# f29h85x_adc_regs register map
Vendor: Texas Instruments
Peripheral module from a debugger description file (folder C29).
Registers are 32-bit, read-write, no defined reset value unless marked. A register's access mark holds for its fields unless they carry their own. Offsets are as the file gives them; lines under a group give offsets from that group; [hi:lo] are bit positions; {n}, {i} and the like mark numbered series; 'fields as' and 'values as' point back to an identical list; <NAME> marks a mode.

## ADC_REGS — ADC Registers
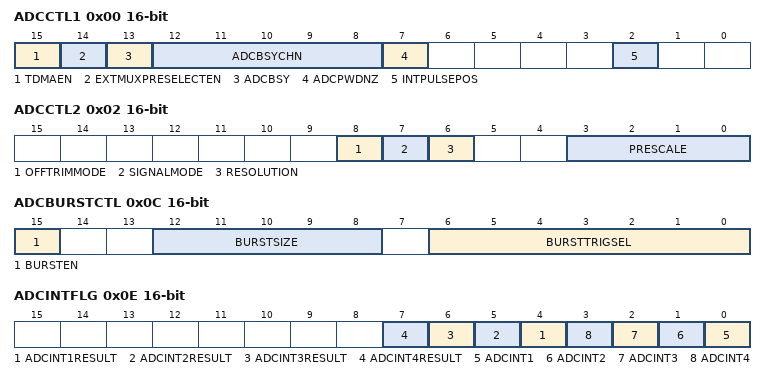
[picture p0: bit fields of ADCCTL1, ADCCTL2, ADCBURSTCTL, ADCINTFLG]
0x00 ADCCTL1 16-bit access per field — ADC Control 1 Register
  [15] TDMAEN rw — Enable Alternate DMA Timings
  [14] EXTMUXPRESELECTEN rw — External Mux Preselect Enable
  [13] ADCBSY ro — ADC Busy
  [12:8] ADCBSYCHN ro — ADC Busy Channel
  [7] ADCPWDNZ rw — ADC Power Down
  [2] INTPULSEPOS rw — ADC Interrupt Pulse Position
0x02 ADCCTL2 16-bit — ADC Control 2 Register
  [8] OFFTRIMMODE — Offset Trim Mode
  [7] SIGNALMODE — SOC Signaling Mode
  [6] RESOLUTION — SOC Conversion Resolution
  [3:0] PRESCALE — ADC Clock Prescaler
0x0C ADCBURSTCTL 16-bit — ADC Burst Control Register
  [15] BURSTEN — SOC Burst Mode Enable
  [12:8] BURSTSIZE — SOC Burst Size Select
  [6:0] BURSTTRIGSEL — SOC Burst Trigger Source Select
0x0E ADCINTFLG 16-bit ro — ADC Interrupt Flag Register
  [n+3] ADCINT{n}RESULT (n=1..4) — ADC Interrupt {n} Results Ready
  [n-1] ADCINT{n} (n=1..4) — ADC Interrupt {n} Flag
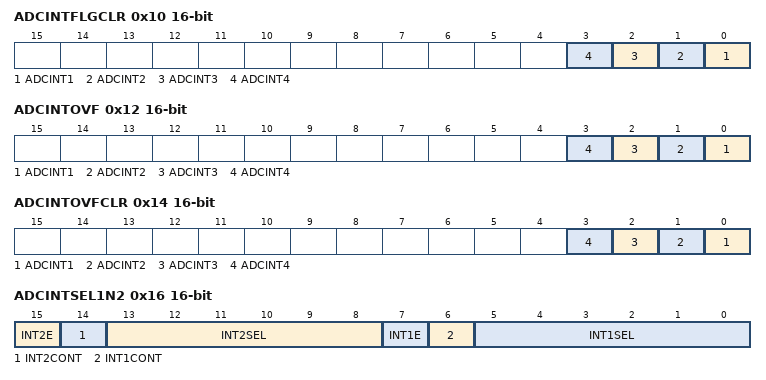
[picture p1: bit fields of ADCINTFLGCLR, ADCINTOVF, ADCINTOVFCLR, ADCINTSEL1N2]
0x10 ADCINTFLGCLR 16-bit — ADC Interrupt Flag Clear Register
  [n-1] ADCINT{n} (n=1..4) — ADC Interrupt {n} Flag Clear
0x12 ADCINTOVF 16-bit ro — ADC Interrupt Overflow Register
  [n-1] ADCINT{n} (n=1..4) — ADC Interrupt {n} Overflow Flags
0x14 ADCINTOVFCLR 16-bit — ADC Interrupt Overflow Clear Register
  [n-1] ADCINT{n} (n=1..4) — ADC Interrupt {n} Overflow Clear Bits
0x16 ADCINTSEL1N2 16-bit — ADC Interrupt 1 and 2 Selection Register
  [15] INT2E — ADCINT2 Interrupt Enable
  [14] INT2CONT — ADCINT2 Continue to Interrupt Mode
  [13:8] INT2SEL — ADCINT2 EOC Source Select
  [7] INT1E — ADCINT1 Interrupt Enable
  [6] INT1CONT — ADCINT1 Continue to Interrupt Mode
  [5:0] INT1SEL — ADCINT1 EOC Source Select
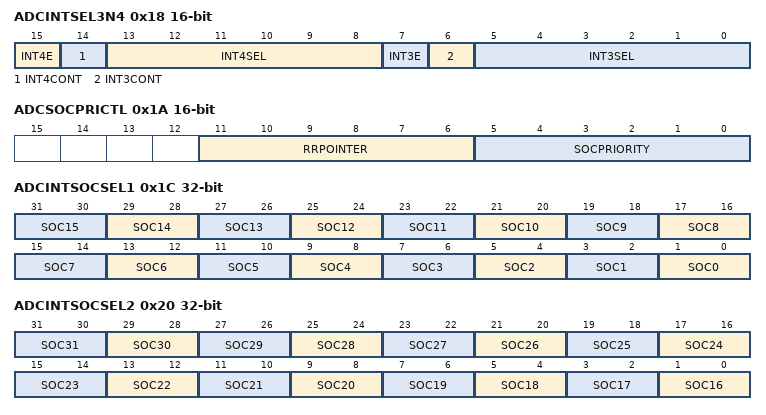
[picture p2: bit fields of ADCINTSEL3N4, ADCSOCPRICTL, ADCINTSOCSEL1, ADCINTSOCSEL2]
0x18 ADCINTSEL3N4 16-bit — ADC Interrupt 3 and 4 Selection Register
  [15] INT4E — ADCINT4 Interrupt Enable
  [14] INT4CONT — ADCINT4 Continue to Interrupt Mode
  [13:8] INT4SEL — ADCINT4 EOC Source Select
  [7] INT3E — ADCINT3 Interrupt Enable
  [6] INT3CONT — ADCINT3 Continue to Interrupt Mode
  [5:0] INT3SEL — ADCINT3 EOC Source Select
0x1A ADCSOCPRICTL 16-bit access per field — ADC SOC Priority Control Register
  [11:6] RRPOINTER ro — Round Robin Pointer
  [5:0] SOCPRIORITY rw
0x1C ADCINTSOCSEL1 — ADC Interrupt SOC Selection 1 Register
  [2n+1:2n] SOC{n} (n=0..15) — SOC{n} ADC Interrupt Trigger Select
0x20 ADCINTSOCSEL2 — ADC Interrupt SOC Selection 2 Register
  [2n-31:2n-32] SOC{n} (n=16..31) — SOC{n} ADC Interrupt Trigger Select
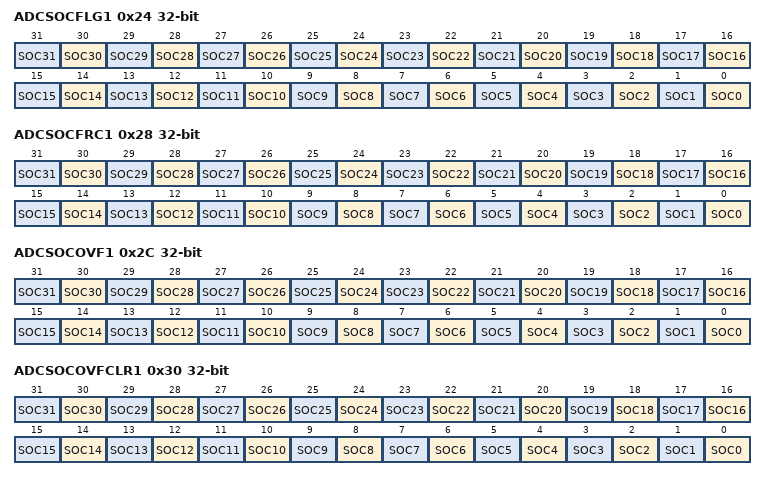
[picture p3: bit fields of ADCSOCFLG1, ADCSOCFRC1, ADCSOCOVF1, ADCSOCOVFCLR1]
0x24 ADCSOCFLG1 ro — ADC SOC Flag 1 Register
  [n] SOC{n} (n=0..31) — SOC{n} Start of Conversion Flag
0x28 ADCSOCFRC1 — ADC SOC Force 1 Register
  [n] SOC{n} (n=0..31) — SOC{n} Force Start of Conversion Bit
0x2C ADCSOCOVF1 ro — ADC SOC Overflow 1 Register
  [n] SOC{n} (n=0..31) — SOC{n} Start of Conversion Overflow Flag
0x30 ADCSOCOVFCLR1 — ADC SOC Overflow Clear 1 Register
  [n] SOC{n} (n=0..31) — SOC{n} Clear Start of Conversion Overflow Bit
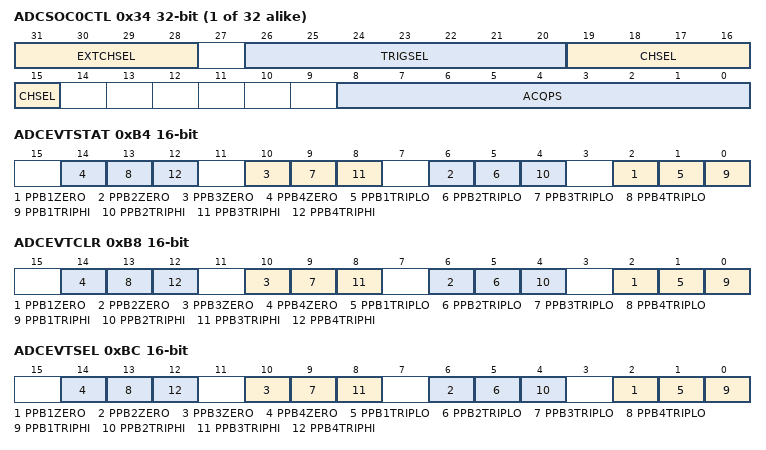
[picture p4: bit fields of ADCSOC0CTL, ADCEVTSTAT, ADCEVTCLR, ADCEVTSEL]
{0x34+4i} ADCSOC{i}CTL (i=0..31) — ADC SOC{i} Control Register
  [31:28] EXTCHSEL — SOC{i} External Channel Mux Select
  [26:20] TRIGSEL — SOC{i} Trigger Source Select
  [19:15] CHSEL — SOC{i} Channel Select
  [8:0] ACQPS — SOC{i} Acquisition Prescale
0xB4 ADCEVTSTAT 16-bit ro — ADC Event Status Register
  [4n-2] PPB{n}ZERO (n=1..4) — Post Processing Block {n} Zero Crossing Flag
  [4n-3] PPB{n}TRIPLO (n=1..4) — Post Processing Block {n} Trip Low Flag
  [4n-4] PPB{n}TRIPHI (n=1..4) — Post Processing Block {n} Trip High Flag
0xB8 ADCEVTCLR 16-bit — ADC Event Clear Register
  [4n-2] PPB{n}ZERO (n=1..4) — Post Processing Block {n} Zero Crossing Clear
  [4n-3] PPB{n}TRIPLO (n=1..4) — Post Processing Block {n} Trip Low Clear
  [4n-4] PPB{n}TRIPHI (n=1..4) — Post Processing Block {n} Trip High Clear
0xBC ADCEVTSEL 16-bit — ADC Event Selection Register
  [4n-2] PPB{n}ZERO (n=1..4) — Post Processing Block {n} Zero Crossing Event Enable
  [4n-3] PPB{n}TRIPLO (n=1..4) — Post Processing Block {n} Trip Low Event Enable
  [4n-4] PPB{n}TRIPHI (n=1..4) — Post Processing Block {n} Trip High Event Enable
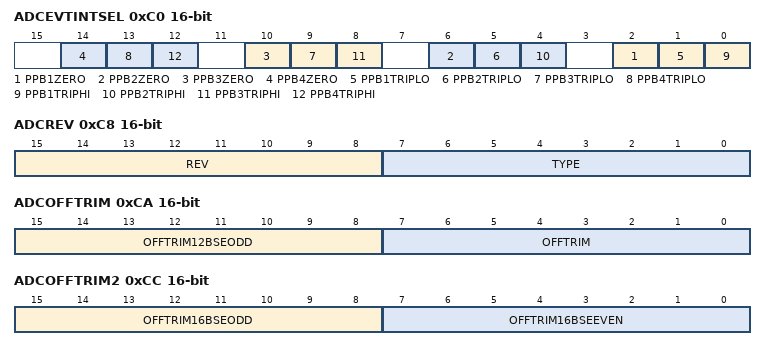
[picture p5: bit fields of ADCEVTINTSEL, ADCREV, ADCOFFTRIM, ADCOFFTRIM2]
0xC0 ADCEVTINTSEL 16-bit — ADC Event Interrupt Selection Register
  [4n-2] PPB{n}ZERO (n=1..4) — Post Processing Block {n} Zero Crossing Interrupt Enable
  [4n-3] PPB{n}TRIPLO (n=1..4) — Post Processing Block {n} Trip Low Interrupt Enable
  [4n-4] PPB{n}TRIPHI (n=1..4) — Post Processing Block {n} Trip High Interrupt Enable
0xC4 ADCOSDETECT 16-bit — ADC Open and Shorts Detect Register
  [2:0] DETECTCFG — ADC Opens and Shorts Detect Configuration
0xC6 ADCCOUNTER 16-bit ro
  [11:0] FREECOUNT — ADC Free Running Counter Value
0xC8 ADCREV 16-bit ro — ADC Revision Register
  [15:8] REV — ADC Revision
  [7:0] TYPE — ADC Type
0xCA ADCOFFTRIM 16-bit — ADC Offset Trim Register 1
  [15:8] OFFTRIM12BSEODD — ADC Offset Trim 12B SE Odd
  [7:0] OFFTRIM — ADC Offset Trim 12B SE Even
0xCC ADCOFFTRIM2 16-bit — ADC Offset Trim Register 2
  [15:8] OFFTRIM16BSEODD — ADC Offset Trim 16B SE Odd
  [7:0] OFFTRIM16BSEEVEN — ADC Offset Trim 16B SE Even
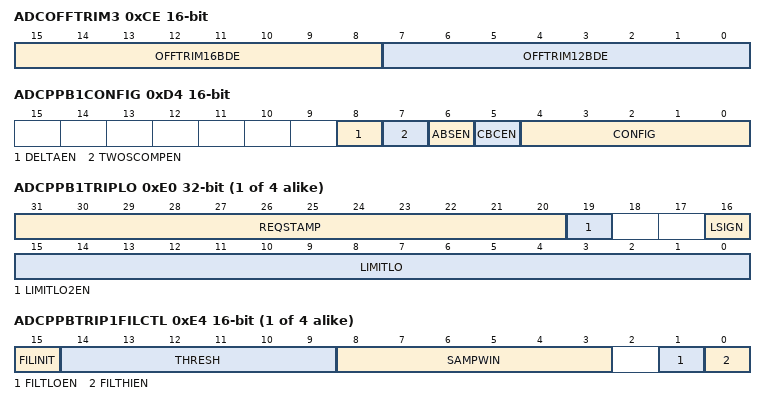
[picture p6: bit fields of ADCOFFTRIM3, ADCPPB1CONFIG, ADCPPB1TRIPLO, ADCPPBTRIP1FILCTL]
0xCE ADCOFFTRIM3 16-bit — ADC Offset Trim Register 3
  [15:8] OFFTRIM16BDE — ADC Offset Trim 16B DE
  [7:0] OFFTRIM12BDE — ADC Offset Trim 12B DE
0xD4 ADCPPB1CONFIG 16-bit — ADC PPB{#} Config Register
  [8] DELTAEN — ADC Post Processing Block 1 Last Sample Delta Enable
  [7] TWOSCOMPEN — ADC Post Processing Block 1 Two's Complement Enable
  [6] ABSEN — ADC Post Processing Block 1 Absolute Enable
  [5] CBCEN — Cycle By Cycle Enable
  [4:0] CONFIG — ADC Post Processing Block 1 Configuration
{0xB6+0x20*i} ADCPPB{i}STAMP 16-bit ro (i=1..4) — ADC PPB{i} Sample Delay Time Stamp Register
  [11:0] DLYSTAMP — ADC Post Processing Block {i} Delay Time Stamp
{0xB8+0x20*i} ADCPPB{i}OFFCAL 16-bit (i=1..4) — ADC PPB{i} Offset Calibration Register
  [9:0] OFFCAL — ADC Post Processing Block Offset Correction
{0xBA+0x20*i} ADCPPB{i}OFFREF 16-bit (i=1..4) — ADC PPB{i} Offset Reference Register
  [15:0] OFFREF — ADC Post Processing Block {i} Offset Reference
{0xBC+0x20*i} ADCPPB{i}TRIPHI (i=1..4) — ADC PPB{i} Trip High Register
  [23:0] LIMITHI — ADC Post Processing Block {i} Trip High Limit
{0xC0+0x20*i} ADCPPB{i}TRIPLO access per field (i=1..4) — ADC PPB{i} Trip Low/Trigger Time Stamp Register
  [31:20] REQSTAMP ro — ADC Post Processing Block {i} Request Time Stamp
  [19] LIMITLO2EN rw — Extended Low Limit 2 Enable
  [16] LSIGN rw — Low Limit Sign Bit
  [15:0] LIMITLO rw — ADC Post Processing Block {i} Trip Low Limit
{0xC4+0x20*i} ADCPPBTRIP{i}FILCTL 16-bit (i=1..4) — ADCEVT{i} Trip High Filter Control Register
  [15] FILINIT — Filter Initialization Bit
  [14:9] THRESH — Majority Voting Threshold
  [8:3] SAMPWIN — Sample Window
  [1] FILTLOEN — ADCPPB{i} TRIPLO Filter Enable
  [0] FILTHIEN — ADCPPB{i} TRIPHI Filter Enable
{0xC8+0x20*i} ADCPPBTRIP{i}FILCLKCTL (i=1..4) — ADCEVT{i} Trip High Filter Prescale Control Register
  [15:0] CLKPRESCALE — Filter Clock Prescale
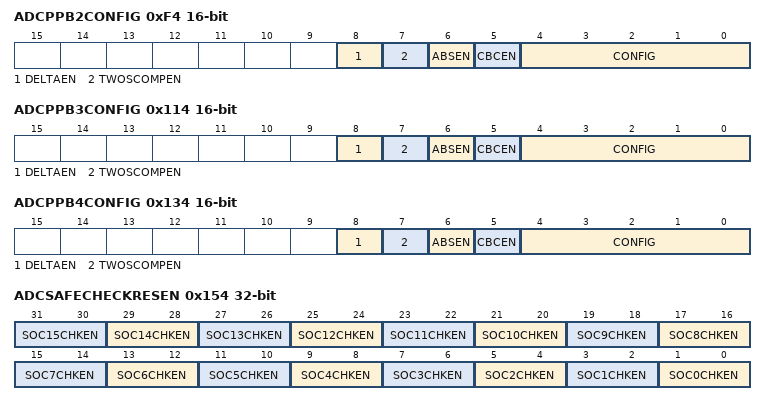
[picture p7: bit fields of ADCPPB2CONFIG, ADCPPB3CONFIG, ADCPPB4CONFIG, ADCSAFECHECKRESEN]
0xF4 ADCPPB2CONFIG 16-bit — ADC PPB{#} Config Register
  [8] DELTAEN — ADC Post Processing Block 2 Last Sample Delta Enable
  [7] TWOSCOMPEN — ADC Post Processing Block 2 Two's Complement Enable
  [6] ABSEN — ADC Post Processing Block 2 Absolute Enable
  [5] CBCEN — Cycle By Cycle Enable
  [4:0] CONFIG — ADC Post Processing Block 2 Configuration
0x114 ADCPPB3CONFIG 16-bit — ADC PPB{#} Config Register
  [8] DELTAEN — ADC Post Processing Block 3 Last Sample Delta Enable
  [7] TWOSCOMPEN — ADC Post Processing Block 3 Two's Complement Enable
  [6] ABSEN — ADC Post Processing Block 3 Absolute Enable
  [5] CBCEN — Cycle By Cycle Enable
  [4:0] CONFIG — ADC Post Processing Block 3 Configuration
0x134 ADCPPB4CONFIG 16-bit — ADC PPB{#} Config Register
  [8] DELTAEN — ADC Post Processing Block 4 Last Sample Delta Enable
  [7] TWOSCOMPEN — ADC Post Processing Block 4 Two's Complement Enable
  [6] ABSEN — ADC Post Processing Block 4 Absolute Enable
  [5] CBCEN — Cycle By Cycle Enable
  [4:0] CONFIG — ADC Post Processing Block 4 Configuration
0x154 ADCSAFECHECKRESEN — ADC Safe Check Result Enable Register
  [2n+1:2n] SOC{n}CHKEN (n=0..15) — ADC SOC{n} Safety Checker Result Enable
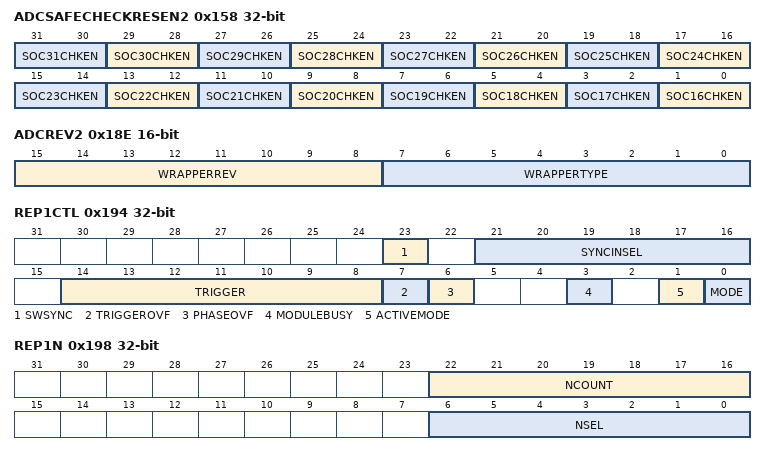
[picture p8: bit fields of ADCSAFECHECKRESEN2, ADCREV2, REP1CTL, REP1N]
0x158 ADCSAFECHECKRESEN2 — ADC Safe Check Result Enable 2 Register
  [2n-31:2n-32] SOC{n}CHKEN (n=16..31) — ADC SOC{n} Safety Checker Result Enable
0x172 ADCINTCYCLE 16-bit — ADC Early Interrupt Generation Cycle
  [15:0] DELAY — Delay from ADCSOC fall edge to early interrupt generation.
{0x170+4i} ADCINLTRIM{i} (i=1..6) — ADC Linearity Trim {i} Register
  [31:0] INLTRIM{32i-1}TO{32i-32} — ADC Linearity Trim Bits {32i-1}-{32i-32}
0x18E ADCREV2 16-bit ro — ADC Wrapper Revision Register
  [15:8] WRAPPERREV — ADC Wrapper Revision
  [7:0] WRAPPERTYPE — ADC Wrapper Type
0x194 REP1CTL access per field — ADC Trigger Repeater 1 Control Register
  [23] SWSYNC rw — ADC Trigger Repeater 1 Software Sync.
  [21:16] SYNCINSEL rw — ADC Trigger Repeater 1 Sync. In Select
  [14:8] TRIGGER rw — ADC Trigger Repeater 1 Trigger Select
  [7] TRIGGEROVF rw — ADC Trigger Repeater 1 Oversampled Trigger Overflow
  [6] PHASEOVF rw — ADC Trigger Repeater 1 Phase Delay Overflow
  [3] MODULEBUSY ro — ADC Trigger Repeater 1 Module Busy
  [1] ACTIVEMODE ro — ADC Trigger Repeater 1 Active Mode
  [0] MODE rw — ADC Trigger Repeater 1 Mode Select
0x198 REP1N access per field — ADC Trigger Repeater 1 N Select Register
  [22:16] NCOUNT ro — ADC Trigger Repeater 1 Trigger Counter
  [6:0] NSEL rw — ADC Trigger Repeater 1 Trigger Number Selection
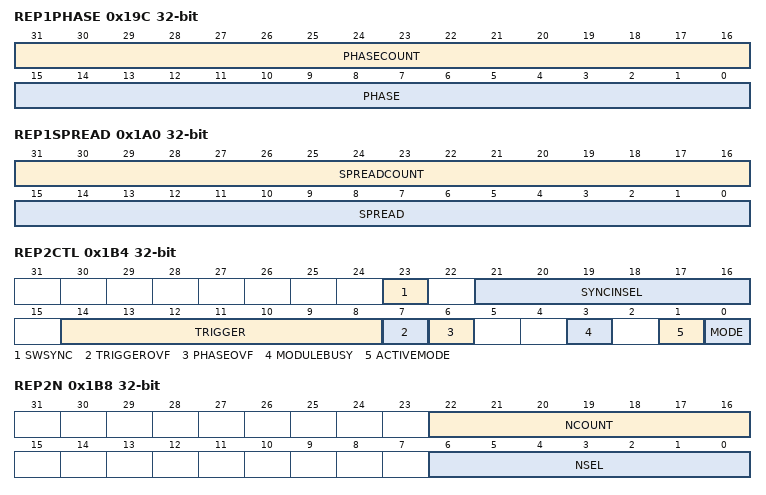
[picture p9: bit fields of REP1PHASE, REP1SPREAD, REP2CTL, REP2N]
0x19C REP1PHASE access per field — ADC Trigger Repeater 1 Phase Select Register
  [31:16] PHASECOUNT ro — ADC Trigger Repeater 1 Phase Delay Status
  [15:0] PHASE rw — ADC Trigger Repeater 1 Phase Delay Configuration
0x1A0 REP1SPREAD access per field — ADC Trigger Repeater 1 Spread Select Register
  [31:16] SPREADCOUNT ro — ADC Trigger Repeater 1 Spread Delay Status
  [15:0] SPREAD rw — ADC Trigger Repeater 1 Spread Delay Configuration
0x1A4 REP1FRC 16-bit — ADC Trigger Repeater 1 Software Force Register
  [0] SWFRC — ADC Trigger Repeater 1 Software Force
0x1B4 REP2CTL access per field — ADC Trigger Repeater 2 Control Register
  [23] SWSYNC rw — ADC Trigger Repeater 2 Software Sync.
  [21:16] SYNCINSEL rw — ADC Trigger Repeater 2 Sync. In Select
  [14:8] TRIGGER rw — ADC Trigger Repeater 2 Trigger Select
  [7] TRIGGEROVF rw — ADC Trigger Repeater 2 Oversampled Trigger Overflow
  [6] PHASEOVF rw — ADC Trigger Repeater 2 Phase Delay Overflow
  [3] MODULEBUSY ro — ADC Trigger Repeater 2 Module Busy
  [1] ACTIVEMODE ro — ADC Trigger Repeater 2 Active Mode
  [0] MODE rw — ADC Trigger Repeater 2 Mode Select
0x1B8 REP2N access per field — ADC Trigger Repeater 2 N Select Register
  [22:16] NCOUNT ro — ADC Trigger Repeater 2 Trigger Counter
  [6:0] NSEL rw — ADC Trigger Repeater 2 Trigger Number Selection
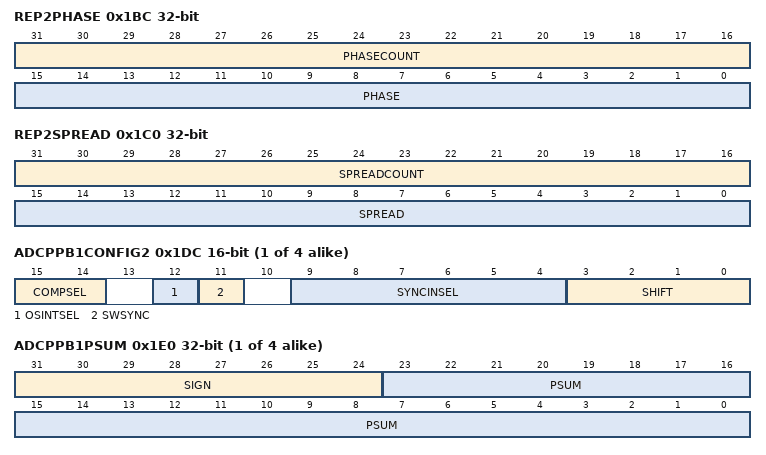
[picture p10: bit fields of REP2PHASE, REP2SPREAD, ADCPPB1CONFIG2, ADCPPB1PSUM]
0x1BC REP2PHASE access per field — ADC Trigger Repeater 2 Phase Select Register
  [31:16] PHASECOUNT ro — ADC Trigger Repeater 2 Phase Delay Status
  [15:0] PHASE rw — ADC Trigger Repeater 2 Phase Delay Configuration
0x1C0 REP2SPREAD access per field — ADC Trigger Repeater 2 Spread Select Register
  [31:16] SPREADCOUNT ro — ADC Trigger Repeater 2 Spread Delay Status
  [15:0] SPREAD rw — ADC Trigger Repeater 2 Spread Delay Configuration
0x1C4 REP2FRC 16-bit — ADC Trigger Repeater 2 Software Force Register
  [0] SWFRC — ADC Trigger Repeater 2 Software Force
{0x1A0+0x34*i} ADCPPB{i}LIMIT 16-bit (i=1..4) — ADC PPB{i}Conversion Count Limit Register
  [9:0] LIMIT — Post Processing Block {i} Limit
{0x1A4+0x34*i} ADCPPBP{i}PCOUNT 16-bit ro (i=1..4) — ADC PPB{i} Partial Conversion Count Register
  [9:0] PCOUNT — Post Processing Block {i} Partial Count
{0x1A8+0x34*i} ADCPPB{i}CONFIG2 16-bit (i=1..4) — ADC PPB{i} Sum Shift Register
  [15:14] COMPSEL — Post Processing Block {i} Compare Source Select
  [12] OSINTSEL — Post Processing Block {i} Interrupt Source Select
  [11] SWSYNC — Post Processing Block {i} Software Force Sync.
  [9:4] SYNCINSEL — Post Processing Block {i} Sync. Input Select
  [3:0] SHIFT — Post Processing Block {i} Right Shift
{0x1AC+0x34*i} ADCPPB{i}PSUM ro (i=1..4) — ADC PPB{i} Partial Sum Register
  [31:24] SIGN — Sign Extended Bits
  [23:0] PSUM — Post Processing Block {i} Oversampling Partial Sum
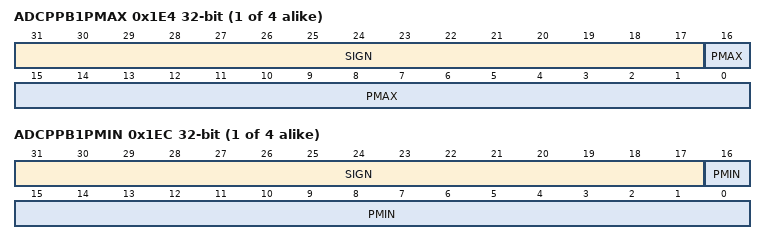
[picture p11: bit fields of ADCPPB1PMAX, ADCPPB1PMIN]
{0x1B0+0x34*i} ADCPPB{i}PMAX ro (i=1..4) — ADC PPB{i} Partial Max Register
  [31:17] SIGN — Sign Extended Bits
  [16:0] PMAX — Post Processing Block {i} Oversampling Partial Max
{0x1B4+0x34*i} ADCPPB{i}PMAXI 16-bit ro (i=1..4) — ADC PPB{i} Partial Max Index Register
  [9:0] PMAXI — Post Processing Block {i} Oversampling Partial Index of Max
{0x1B8+0x34*i} ADCPPB{i}PMIN ro (i=1..4) — ADC PPB{i} Partial MIN Register
  [31:17] SIGN — Sign Extended Bits
  [16:0] PMIN — Post Processing Block {i} Oversampling Partial Min
{0x1BC+0x34*i} ADCPPB{i}PMINI 16-bit ro (i=1..4) — ADC PPB{i} Partial Min Index Register
  [9:0] PMINI — Post Processing Block {i} Oversampling Partial Index of Min
{0x1C0+0x34*i} ADCPPB{i}TRIPLO2 (i=1..4) — ADC PPB{i} Extended Trip Low Register
  [23:0] LIMITLO — ADC Post Processing Block {i} Trip Low Limit
